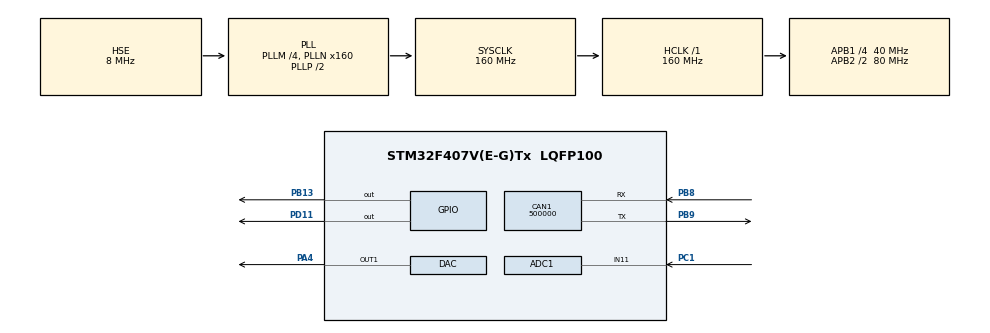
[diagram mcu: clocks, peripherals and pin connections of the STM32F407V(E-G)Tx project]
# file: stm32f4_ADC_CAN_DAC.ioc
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ADC1.Channel-0\#ChannelRegularConversion=ADC_CHANNEL_11
ADC1.ContinuousConvMode=ENABLE
ADC1.DMAContinuousRequests=ENABLE
ADC1.NbrOfConversionFlag=1
ADC1.Rank-0\#ChannelRegularConversion=1
ADC1.SamplingTime-0\#ChannelRegularConversion=ADC_SAMPLETIME_480CYCLES
ADC1.ScanConvMode=ENABLE
ADC1.master=1
CAN1.ABOM=DISABLE
CAN1.AWUM=DISABLE
CAN1.BS1=CAN_BS1_2TQ
CAN1.BS2=CAN_BS2_2TQ
CAN1.CalculateBaudRate=500000
CAN1.CalculateTimeBit=2000
CAN1.CalculateTimeQuantum=400.0
Dma.ADC1.0.Direction=DMA_PERIPH_TO_MEMORY
Dma.ADC1.0.FIFOMode=DMA_FIFOMODE_DISABLE
Dma.ADC1.0.Instance=DMA2_Stream0
Dma.ADC1.0.MemDataAlignment=DMA_MDATAALIGN_WORD
Dma.ADC1.0.MemInc=DMA_MINC_ENABLE
Dma.ADC1.0.Mode=DMA_CIRCULAR
Dma.ADC1.0.PeriphDataAlignment=DMA_PDATAALIGN_WORD
Dma.ADC1.0.PeriphInc=DMA_PINC_DISABLE
Dma.ADC1.0.Priority=DMA_PRIORITY_LOW
Dma.Request0=ADC1
Mcu.Family=STM32F4
Mcu.Name=STM32F407V(E-G)Tx
Mcu.Package=LQFP100
NVIC.ADC_IRQn=true\:0\:0\:false\:false\:true\:true\:true\:true
NVIC.CAN1_RX0_IRQn=true\:0\:0\:false\:false\:true\:true\:true\:true
NVIC.CAN1_RX1_IRQn=true\:0\:0\:false\:false\:true\:true\:true\:true
NVIC.DMA2_Stream0_IRQn=true\:0\:0\:false\:false\:true\:false\:true\:true
NVIC.PriorityGroup=NVIC_PRIORITYGROUP_4
PA13.Mode=Serial_Wire
PA13.Signal=SYS_JTMS-SWDIO
PA14.Mode=Serial_Wire
PA14.Signal=SYS_JTCK-SWCLK
PA4.Signal=COMP_DAC1_group
PB13.Signal=GPIO_Output
PB8.Mode=CAN_Activate
PB8.Signal=CAN1_RX
PB9.Mode=CAN_Activate
PB9.Signal=CAN1_TX
PC1.Signal=ADCx_IN11
PD11.Signal=GPIO_Output
PH0-OSC_IN.Mode=HSE-External-Oscillator
PH0-OSC_IN.Signal=RCC_OSC_IN
PH1-OSC_OUT.Mode=HSE-External-Oscillator
PH1-OSC_OUT.Signal=RCC_OSC_OUT
ProjectManager.HeapSize=0x200
ProjectManager.StackSize=0x400
ProjectManager.TargetToolchain=MDK-ARM V5.32
RCC.48MHZClocksFreq_Value=80000000
RCC.AHBFreq_Value=160000000
RCC.APB1CLKDivider=RCC_HCLK_DIV4
RCC.APB1Freq_Value=40000000
RCC.APB1TimFreq_Value=80000000
RCC.APB2CLKDivider=RCC_HCLK_DIV2
RCC.APB2Freq_Value=80000000
RCC.APB2TimFreq_Value=160000000
RCC.CortexFreq_Value=160000000
RCC.HCLKFreq_Value=160000000
RCC.HSE_VALUE=8000000
RCC.HSI_VALUE=16000000
RCC.LSE_VALUE=32768
RCC.PLLM=4
RCC.PLLN=160
RCC.PLLSourceVirtual=RCC_PLLSOURCE_HSE
RCC.SYSCLKFreq_VALUE=160000000
RCC.SYSCLKSource=RCC_SYSCLKSOURCE_PLLCLK
RCC.VCOOutputFreq_Value=320000000
SH.ADCx_IN11.0=ADC1_IN11,IN11
SH.COMP_DAC1_group.0=DAC_OUT1,DAC_OUT1
board=custom

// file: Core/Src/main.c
#include "main.h"

ADC_HandleTypeDef hadc1;
DMA_HandleTypeDef hdma_adc1;

CAN_HandleTypeDef hcan1;

DAC_HandleTypeDef hdac;

void SystemClock_Config(void);
static void MX_GPIO_Init(void);
static void MX_DMA_Init(void);
static void MX_ADC1_Init(void);
static void MX_CAN1_Init(void);
static void MX_DAC_Init(void);
void int2str4(uint16_t adc, uint8_t *y);
void invert2(uint32_t *trans_can, uint8_t *y);
//-------------------------------------------------------------------------------------
CAN_TxHeaderTypeDef TxHeader;
CAN_RxHeaderTypeDef RxHeader;

uint8_t TxData[4];
uint8_t RxData[4];
uint32_t TxMailbox;

int datacheck = 0;
uint32_t adc_value;
int dac;
//--------------------------------------------------------------------------------------

void HAL_CAN_RxFifo0MsgPendingCallback(CAN_HandleTypeDef *hcan)
{
	HAL_CAN_GetRxMessage(hcan, CAN_RX_FIFO0, &RxHeader, RxData);
	datacheck = 1;
	//HAL_GPIO_TogglePin(GPIOD, GPIO_PIN_11);
	//HAL_Delay(200);
	dac =(RxData[0] - 0x30)*1000  + (RxData[1]- 0x30)*100  +(RxData[2]- 0x30)*10 +(RxData[3]-0x30);
	HAL_DAC_SetValue(&hdac, DAC_CHANNEL_1, DAC_ALIGN_12B_R, dac);
}
//------------------------------------------------------
int main(void)
{

  HAL_Init();

  SystemClock_Config();

  MX_GPIO_Init();
  MX_DMA_Init();
  MX_ADC1_Init();
  MX_CAN1_Init();
  MX_DAC_Init();

	HAL_DAC_Start(&hdac, DAC_CHANNEL_1);

	HAL_ADC_Start_DMA(&hadc1, &adc_value, 1);

  HAL_CAN_Start(&hcan1);

  HAL_CAN_ActivateNotification(&hcan1, CAN_IT_RX_FIFO0_MSG_PENDING);

  TxHeader.DLC = 4;  // data length
  TxHeader.IDE = CAN_ID_STD;
  TxHeader.RTR = CAN_RTR_DATA;
  TxHeader.StdId = 0x103;  // ID

  while (1)
  {
			int2str4(adc_value, TxData );
			HAL_CAN_AddTxMessage(&hcan1, &TxHeader, TxData, &TxMailbox);
			HAL_Delay(200);
			if (datacheck ==1)
			{

				datacheck =0;
			}
  }
}
//----------------------------------------------------------------
void int2str4(uint16_t adc, uint8_t *y)
{

   	y[0] = adc / 1000 + 0x30;
			adc = adc % 1000;
		y[1] = adc / 100 + 0x30;
			adc = adc % 100;
		y[2] = adc / 10 + 0x30;
		y[3] = adc % 10 + 0x30;
}

//-------------------------------------------
void SystemClock_Config(void)
{
  RCC_OscInitTypeDef RCC_OscInitStruct = {0};
  RCC_ClkInitTypeDef RCC_ClkInitStruct = {0};

  /** Configure the main internal regulator output voltage
  */
  __HAL_RCC_PWR_CLK_ENABLE();
  __HAL_PWR_VOLTAGESCALING_CONFIG(PWR_REGULATOR_VOLTAGE_SCALE1);

  /** Initializes the RCC Oscillators according to the specified parameters
  * in the RCC_OscInitTypeDef structure.
  */
  RCC_OscInitStruct.OscillatorType = RCC_OSCILLATORTYPE_HSE;
  RCC_OscInitStruct.HSEState = RCC_HSE_ON;
  RCC_OscInitStruct.PLL.PLLState = RCC_PLL_ON;
  RCC_OscInitStruct.PLL.PLLSource = RCC_PLLSOURCE_HSE;
  RCC_OscInitStruct.PLL.PLLM = 4;
  RCC_OscInitStruct.PLL.PLLN = 160;
  RCC_OscInitStruct.PLL.PLLP = RCC_PLLP_DIV2;
  RCC_OscInitStruct.PLL.PLLQ = 4;
  if (HAL_RCC_OscConfig(&RCC_OscInitStruct) != HAL_OK)
  {
    Error_Handler();
  }

  /** Initializes the CPU, AHB and APB buses clocks
  */
  RCC_ClkInitStruct.ClockType = RCC_CLOCKTYPE_HCLK|RCC_CLOCKTYPE_SYSCLK
                              |RCC_CLOCKTYPE_PCLK1|RCC_CLOCKTYPE_PCLK2;
  RCC_ClkInitStruct.SYSCLKSource = RCC_SYSCLKSOURCE_PLLCLK;
  RCC_ClkInitStruct.AHBCLKDivider = RCC_SYSCLK_DIV1;
  RCC_ClkInitStruct.APB1CLKDivider = RCC_HCLK_DIV4;
  RCC_ClkInitStruct.APB2CLKDivider = RCC_HCLK_DIV2;

  if (HAL_RCC_ClockConfig(&RCC_ClkInitStruct, FLASH_LATENCY_5) != HAL_OK)
  {
    Error_Handler();
  }
}

static void MX_ADC1_Init(void)
{

  ADC_ChannelConfTypeDef sConfig = {0};

  /** Configure the global features of the ADC (Clock, Resolution, Data Alignment and number of conversion)
  */
  hadc1.Instance = ADC1;
  hadc1.Init.ClockPrescaler = ADC_CLOCK_SYNC_PCLK_DIV4;
  hadc1.Init.Resolution = ADC_RESOLUTION_12B;
  hadc1.Init.ScanConvMode = ENABLE;
  hadc1.Init.ContinuousConvMode = ENABLE;
  hadc1.Init.DiscontinuousConvMode = DISABLE;
  hadc1.Init.ExternalTrigConvEdge = ADC_EXTERNALTRIGCONVEDGE_NONE;
  hadc1.Init.ExternalTrigConv = ADC_SOFTWARE_START;
  hadc1.Init.DataAlign = ADC_DATAALIGN_RIGHT;
  hadc1.Init.NbrOfConversion = 1;
  hadc1.Init.DMAContinuousRequests = ENABLE;
  hadc1.Init.EOCSelection = ADC_EOC_SINGLE_CONV;
  if (HAL_ADC_Init(&hadc1) != HAL_OK)
  {
    Error_Handler();
  }

  /** Configure for the selected ADC regular channel its corresponding rank in the sequencer and its sample time.
  */
  sConfig.Channel = ADC_CHANNEL_11;
  sConfig.Rank = 1;
  sConfig.SamplingTime = ADC_SAMPLETIME_480CYCLES;
  if (HAL_ADC_ConfigChannel(&hadc1, &sConfig) != HAL_OK)
  {
    Error_Handler();
  }

}

static void MX_CAN1_Init(void)
{

  hcan1.Instance = CAN1;
  hcan1.Init.Prescaler = 16;
  hcan1.Init.Mode = CAN_MODE_NORMAL;
  hcan1.Init.SyncJumpWidth = CAN_SJW_1TQ;
  hcan1.Init.TimeSeg1 = CAN_BS1_2TQ;
  hcan1.Init.TimeSeg2 = CAN_BS2_2TQ;
  hcan1.Init.TimeTriggeredMode = DISABLE;
  hcan1.Init.AutoBusOff = DISABLE;
  hcan1.Init.AutoWakeUp = DISABLE;
  hcan1.Init.AutoRetransmission = DISABLE;
  hcan1.Init.ReceiveFifoLocked = DISABLE;
  hcan1.Init.TransmitFifoPriority = DISABLE;
  if (HAL_CAN_Init(&hcan1) != HAL_OK)
  {
    Error_Handler();
  }
  /* USER CODE BEGIN CAN1_Init 2 */
	CAN_FilterTypeDef canfilterconfig;

  canfilterconfig.FilterActivation = CAN_FILTER_ENABLE;
  canfilterconfig.FilterBank = 10;  // anything between 0 to SlaveStartFilterBank
  canfilterconfig.FilterFIFOAssignment = CAN_RX_FIFO0;
  canfilterconfig.FilterIdHigh = 0x446<<5;
  canfilterconfig.FilterIdLow = 0x0000;
  canfilterconfig.FilterMaskIdHigh = 0x446<<5;
  canfilterconfig.FilterMaskIdLow = 0x0000;
  canfilterconfig.FilterMode = CAN_FILTERMODE_IDMASK;
  canfilterconfig.FilterScale = CAN_FILTERSCALE_32BIT;
  canfilterconfig.SlaveStartFilterBank = 0;  // 13 to 27 are assigned to slave CAN (CAN 2) OR 0 to 12 are assgned to CAN1

  HAL_CAN_ConfigFilter(&hcan1, &canfilterconfig);
  /* USER CODE END CAN1_Init 2 */

}

static void MX_DAC_Init(void)
{

  DAC_ChannelConfTypeDef sConfig = {0};

  /** DAC Initialization
  */
  hdac.Instance = DAC;
  if (HAL_DAC_Init(&hdac) != HAL_OK)
  {
    Error_Handler();
  }

  /** DAC channel OUT1 config
  */
  sConfig.DAC_Trigger = DAC_TRIGGER_NONE;
  sConfig.DAC_OutputBuffer = DAC_OUTPUTBUFFER_ENABLE;
  if (HAL_DAC_ConfigChannel(&hdac, &sConfig, DAC_CHANNEL_1) != HAL_OK)
  {
    Error_Handler();
  }

}

static void MX_DMA_Init(void)
{

  /* DMA controller clock enable */
  __HAL_RCC_DMA2_CLK_ENABLE();

  /* DMA interrupt init */
  /* DMA2_Stream0_IRQn interrupt configuration */
  HAL_NVIC_SetPriority(DMA2_Stream0_IRQn, 0, 0);
  HAL_NVIC_EnableIRQ(DMA2_Stream0_IRQn);

}

static void MX_GPIO_Init(void)
{
  GPIO_InitTypeDef GPIO_InitStruct = {0};

  /* GPIO Ports Clock Enable */
  __HAL_RCC_GPIOH_CLK_ENABLE();
  __HAL_RCC_GPIOC_CLK_ENABLE();
  __HAL_RCC_GPIOA_CLK_ENABLE();
  __HAL_RCC_GPIOB_CLK_ENABLE();
  __HAL_RCC_GPIOD_CLK_ENABLE();

  /*Configure GPIO pin Output Level */
  HAL_GPIO_WritePin(GPIOB, GPIO_PIN_13, GPIO_PIN_RESET);

  /*Configure GPIO pin Output Level */
  HAL_GPIO_WritePin(GPIOD, GPIO_PIN_11, GPIO_PIN_RESET);

  /*Configure GPIO pin : PB13 */
  GPIO_InitStruct.Pin = GPIO_PIN_13;
  GPIO_InitStruct.Mode = GPIO_MODE_OUTPUT_PP;
  GPIO_InitStruct.Pull = GPIO_NOPULL;
  GPIO_InitStruct.Speed = GPIO_SPEED_FREQ_LOW;
  HAL_GPIO_Init(GPIOB, &GPIO_InitStruct);

  /*Configure GPIO pin : PD11 */
  GPIO_InitStruct.Pin = GPIO_PIN_11;
  GPIO_InitStruct.Mode = GPIO_MODE_OUTPUT_PP;
  GPIO_InitStruct.Pull = GPIO_NOPULL;
  GPIO_InitStruct.Speed = GPIO_SPEED_FREQ_LOW;
  HAL_GPIO_Init(GPIOD, &GPIO_InitStruct);

}

void Error_Handler(void)
{
  __disable_irq();
  while (1)
  {
  }
}
